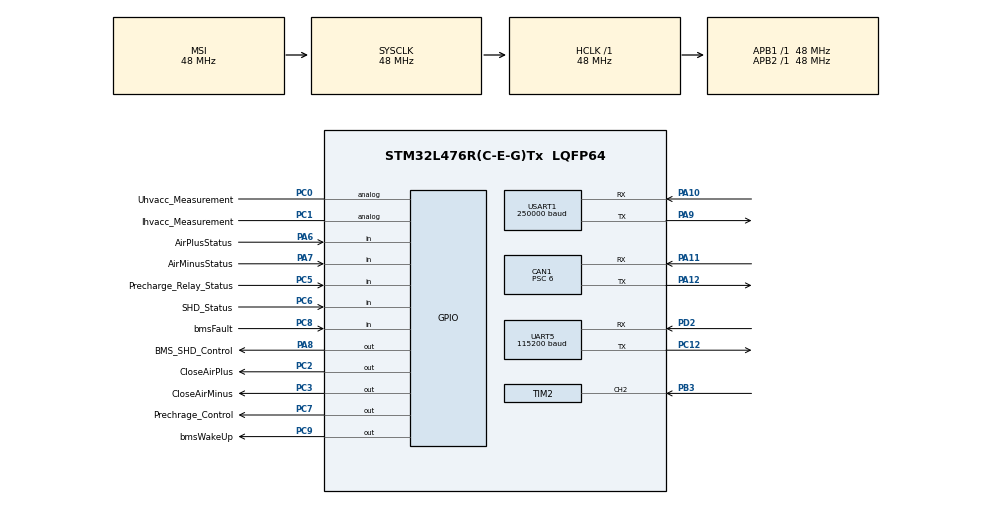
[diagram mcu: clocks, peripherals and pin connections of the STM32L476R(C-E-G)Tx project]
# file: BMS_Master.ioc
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CAN1.BS1=CAN_BS1_13TQ
CAN1.BS2=CAN_BS2_2TQ
CAN1.CalculateBaudRate=500000
CAN1.CalculateTimeBit=2000.00
CAN1.CalculateTimeQuantum=125.0
CAN1.Prescaler=6
Dma.Request0=USART1_RX
Dma.USART1_RX.0.Direction=DMA_PERIPH_TO_MEMORY
Dma.USART1_RX.0.Instance=DMA1_Channel5
Dma.USART1_RX.0.MemDataAlignment=DMA_MDATAALIGN_BYTE
Dma.USART1_RX.0.MemInc=DMA_MINC_ENABLE
Dma.USART1_RX.0.Mode=DMA_NORMAL
Dma.USART1_RX.0.PeriphDataAlignment=DMA_PDATAALIGN_BYTE
Dma.USART1_RX.0.PeriphInc=DMA_PINC_DISABLE
Dma.USART1_RX.0.Priority=DMA_PRIORITY_LOW
Mcu.Family=STM32L4
Mcu.Name=STM32L476R(C-E-G)Tx
Mcu.Package=LQFP64
NVIC.CAN1_RX0_IRQn=true\:0\:0\:false\:false\:true\:true\:true
NVIC.CAN1_RX1_IRQn=true\:0\:0\:false\:false\:true\:true\:true
NVIC.DMA1_Channel5_IRQn=true\:0\:0\:false\:false\:true\:false\:true
NVIC.PriorityGroup=NVIC_PRIORITYGROUP_4
NVIC.TIM1_UP_TIM16_IRQn=true\:15\:0\:false\:false\:true\:false\:true
NVIC.TIM2_IRQn=true\:0\:0\:false\:false\:true\:true\:true
NVIC.TIM5_IRQn=true\:0\:0\:false\:false\:true\:true\:true
NVIC.TimeBase=TIM1_UP_TIM16_IRQn
NVIC.TimeBaseIP=TIM1
NVIC.UART5_IRQn=true\:0\:0\:false\:false\:true\:true\:true
NVIC.USART1_IRQn=true\:0\:0\:false\:false\:true\:true\:true
PA10.Mode=Asynchronous
PA10.Signal=USART1_RX
PA11.Mode=CAN_Activate
PA11.Signal=CAN1_RX
PA12.Mode=CAN_Activate
PA12.Signal=CAN1_TX
PA6.GPIO_Label=AirPlusStatus
PA6.Signal=GPIO_Input
PA7.GPIO_Label=AirMinusStatus
PA7.Signal=GPIO_Input
PA8.GPIO_Label=BMS_SHD_Control
PA8.Signal=GPIO_Output
PA9.Mode=Asynchronous
PA9.Signal=USART1_TX
PB3\ (JTDO-TRACESWO).Signal=S_TIM2_CH2
PC0.GPIO_Label=Uhvacc_Measurement
PC0.Signal=GPIO_Analog
PC1.GPIO_Label=Ihvacc_Measurement
PC1.Signal=GPIO_Analog
PC12.Mode=Asynchronous
PC12.Signal=UART5_TX
PC2.GPIO_Label=CloseAirPlus
PC2.Signal=GPIO_Output
PC3.GPIO_Label=CloseAirMinus
PC3.Signal=GPIO_Output
PC5.GPIO_Label=Precharge_Relay_Status
PC5.Signal=GPIO_Input
PC6.GPIO_Label=SHD_Status
PC6.Signal=GPIO_Input
PC7.GPIO_Label=Prechrage_Control
PC7.Signal=GPIO_Output
PC8.GPIO_Label=bmsFault
PC8.Signal=GPIO_Input
PC9.GPIO_Label=bmsWakeUp
PC9.Signal=GPIO_Output
PD2.Mode=Asynchronous
PD2.Signal=UART5_RX
ProjectManager.HeapSize=0x200
ProjectManager.StackSize=0x400
ProjectManager.TargetToolchain=STM32CubeIDE
RCC.ADCFreq_Value=192000000
RCC.AHBFreq_Value=48000000
RCC.APB1Freq_Value=48000000
RCC.APB1TimFreq_Value=48000000
RCC.APB2Freq_Value=48000000
RCC.APB2TimFreq_Value=48000000
RCC.CortexFreq_Value=48000000
RCC.HCLKFreq_Value=48000000
RCC.HSE_VALUE=8000000
RCC.HSI_VALUE=16000000
RCC.LSE_VALUE=32768
RCC.MSIClockRange=RCC_MSIRANGE_11
RCC.MSI_VALUE=48000000
RCC.SYSCLKFreq_VALUE=48000000
RCC.USBFreq_Value=192000000
RCC.VCOOutputFreq_Value=384000000
SH.S_TIM2_CH2.0=TIM2_CH2,PWM_Input_2
TIM2.ICPolarity_1=TIM_INPUTCHANNELPOLARITY_RISING
TIM4.Period=100
TIM4.Prescaler=4000
TIM5.Period=100
TIM5.Prescaler=2000
UART5.BaudRate=115200
UART5.DMADisableonRxErrorParam=UART_ADVFEATURE_DMA_ENABLEONRXERROR
UART5.WordLength=WORDLENGTH_8B
USART1.BaudRate=250000
USART1.VirtualMode-Asynchronous=VM_ASYNC
USART1.WordLength=WORDLENGTH_8B
VP_SYS_VS_tim1.Mode=TIM1
VP_TIM4_VS_ClockSourceINT.Mode=Internal
VP_TIM4_VS_OPM.Mode=OPM_bit
VP_TIM5_VS_ClockSourceINT.Mode=Internal
board=custom

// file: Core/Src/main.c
/* USER CODE BEGIN Header */
/**
  ******************************************************************************
  * @file           : main.c
  * @brief          : Main program body
  ******************************************************************************
  * @attention
  *
  * <h2><center>&copy; Copyright (c) 2022 STMicroelectronics.
  * All rights reserved.</center></h2>
  *
  * This software component is licensed by ST under BSD 3-Clause license,
  * the "License"; You may not use this file except in compliance with the
  * License. You may obtain a copy of the License at:
  *                        opensource.org/licenses/BSD-3-Clause
  *
  ******************************************************************************
  */
/* USER CODE END Header */
#include "main.h"
#include "can.h"
#include "dma.h"
#include "tim.h"
#include "usart.h"
#include "gpio.h"

/* USER CODE BEGIN Includes */
#include "userMian.h"
extern void Can_Init();
extern void userMainInit();
extern int WriteReg(char bID, uint16_t wAddr, uint64_t dwData, char bLen, char bWriteType) ;
/* USER CODE END Includes */

void SystemClock_Config(void);

int main(void)
{

  /* MCU Configuration--------------------------------------------------------*/

  /* Reset of all peripherals, Initializes the Flash interface and the Systick. */
  HAL_Init();

  /* Configure the system clock */
  SystemClock_Config();

  /* Initialize all configured peripherals */
  MX_GPIO_Init();
  MX_TIM2_Init();
  MX_USART1_UART_Init();
  MX_UART5_Init();
  MX_CAN1_Init();
  MX_TIM4_Init();
  MX_DMA_Init();
  MX_TIM5_Init();
  /* USER CODE BEGIN 2 */

  userMainInit();
  userMain();

  /* USER CODE END 2 */

  /* Infinite loop */
  while(1){

  }
}

void SystemClock_Config(void)
{
  RCC_OscInitTypeDef RCC_OscInitStruct = {0};
  RCC_ClkInitTypeDef RCC_ClkInitStruct = {0};

  /** Configure the main internal regulator output voltage
  */
  if (HAL_PWREx_ControlVoltageScaling(PWR_REGULATOR_VOLTAGE_SCALE1) != HAL_OK)
  {
    Error_Handler();
  }
  /** Initializes the RCC Oscillators according to the specified parameters
  * in the RCC_OscInitTypeDef structure.
  */
  RCC_OscInitStruct.OscillatorType = RCC_OSCILLATORTYPE_MSI;
  RCC_OscInitStruct.MSIState = RCC_MSI_ON;
  RCC_OscInitStruct.MSICalibrationValue = 0;
  RCC_OscInitStruct.MSIClockRange = RCC_MSIRANGE_11;
  RCC_OscInitStruct.PLL.PLLState = RCC_PLL_NONE;
  if (HAL_RCC_OscConfig(&RCC_OscInitStruct) != HAL_OK)
  {
    Error_Handler();
  }
  /** Initializes the CPU, AHB and APB buses clocks
  */
  RCC_ClkInitStruct.ClockType = RCC_CLOCKTYPE_HCLK|RCC_CLOCKTYPE_SYSCLK
                              |RCC_CLOCKTYPE_PCLK1|RCC_CLOCKTYPE_PCLK2;
  RCC_ClkInitStruct.SYSCLKSource = RCC_SYSCLKSOURCE_MSI;
  RCC_ClkInitStruct.AHBCLKDivider = RCC_SYSCLK_DIV1;
  RCC_ClkInitStruct.APB1CLKDivider = RCC_HCLK_DIV1;
  RCC_ClkInitStruct.APB2CLKDivider = RCC_HCLK_DIV1;

  if (HAL_RCC_ClockConfig(&RCC_ClkInitStruct, FLASH_LATENCY_2) != HAL_OK)
  {
    Error_Handler();
  }
}

void HAL_TIM_PeriodElapsedCallback(TIM_HandleTypeDef *htim)
{
  if (htim->Instance == TIM1) {
    HAL_IncTick();
  }
}

void Error_Handler(void)
{
  __disable_irq();
  while (1)
  {
  }
}

/************************ (C) COPYRIGHT STMicroelectronics *****END OF FILE****/
